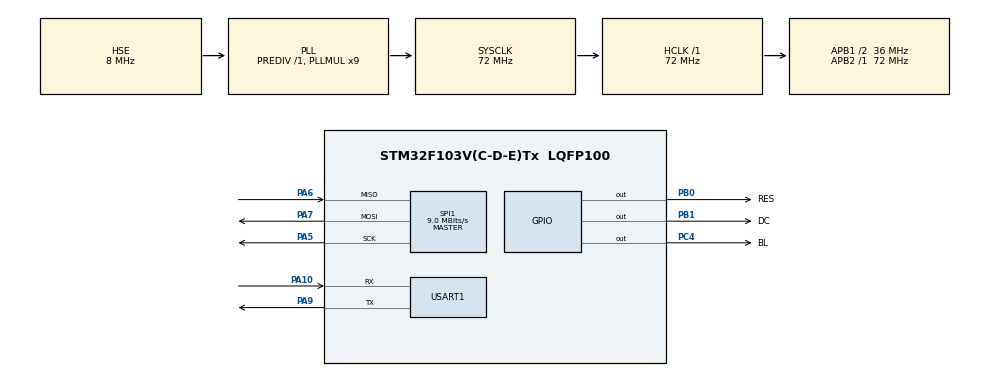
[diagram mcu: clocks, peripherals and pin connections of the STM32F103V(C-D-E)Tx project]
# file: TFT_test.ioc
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Mcu.Family=STM32F1
Mcu.Name=STM32F103V(C-D-E)Tx
Mcu.Package=LQFP100
NVIC.PriorityGroup=NVIC_PRIORITYGROUP_4
NVIC.USART1_IRQn=true\:0\:0\:false\:false\:true\:true\:true\:true
OSC_IN.Mode=HSE-External-Oscillator
OSC_IN.Signal=RCC_OSC_IN
OSC_OUT.Mode=HSE-External-Oscillator
OSC_OUT.Signal=RCC_OSC_OUT
PA10.Mode=Asynchronous
PA10.Signal=USART1_RX
PA13.Mode=JTAG_5_pins
PA13.Signal=SYS_JTMS-SWDIO
PA14.Mode=JTAG_5_pins
PA14.Signal=SYS_JTCK-SWCLK
PA15.Mode=JTAG_5_pins
PA15.Signal=SYS_JTDI
PA5.Mode=Full_Duplex_Master
PA5.Signal=SPI1_SCK
PA6.Mode=Full_Duplex_Master
PA6.Signal=SPI1_MISO
PA7.Mode=Full_Duplex_Master
PA7.Signal=SPI1_MOSI
PA9.Mode=Asynchronous
PA9.Signal=USART1_TX
PB0.GPIO_Label=RES
PB0.GPIO_Speed=GPIO_SPEED_FREQ_HIGH
PB0.PinState=GPIO_PIN_SET
PB0.Signal=GPIO_Output
PB1.GPIO_Label=DC
PB1.GPIO_Speed=GPIO_SPEED_FREQ_HIGH
PB1.PinState=GPIO_PIN_SET
PB1.Signal=GPIO_Output
PB3.Mode=JTAG_5_pins
PB3.Signal=SYS_JTDO-TRACESWO
PB4.Mode=JTAG_5_pins
PB4.Signal=SYS_NJTRST
PC4.GPIO_Label=BL
PC4.PinState=GPIO_PIN_SET
PC4.Signal=GPIO_Output
ProjectManager.HeapSize=0x200
ProjectManager.StackSize=0x400
ProjectManager.TargetToolchain=Makefile
RCC.AHBFreq_Value=72000000
RCC.APB1CLKDivider=RCC_HCLK_DIV2
RCC.APB1Freq_Value=36000000
RCC.APB1TimFreq_Value=72000000
RCC.APB2Freq_Value=72000000
RCC.APB2TimFreq_Value=72000000
RCC.HCLKFreq_Value=72000000
RCC.PLLMUL=RCC_PLL_MUL9
RCC.PLLSourceVirtual=RCC_PLLSOURCE_HSE
RCC.SYSCLKFreq_VALUE=72000000
RCC.SYSCLKSource=RCC_SYSCLKSOURCE_PLLCLK
RCC.USBFreq_Value=72000000
SPI1.BaudRatePrescaler=SPI_BAUDRATEPRESCALER_8
SPI1.CLKPolarity=SPI_POLARITY_HIGH
SPI1.CalculateBaudRate=9.0 MBits/s
SPI1.Direction=SPI_DIRECTION_2LINES
SPI1.Mode=SPI_MODE_MASTER
SPI1.VirtualType=VM_MASTER
USART1.VirtualMode=VM_ASYNC
board=custom

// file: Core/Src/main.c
/* USER CODE BEGIN Header */
/**
 ******************************************************************************
 * @file           : main.c
 * @brief          : Main program body
 ******************************************************************************
 * @attention
 *
 * Copyright (c) 2023 STMicroelectronics.
 * All rights reserved.
 *
 * This software is licensed under terms that can be found in the LICENSE file
 * in the root directory of this software component.
 * If no LICENSE file comes with this software, it is provided AS-IS.
 *
 ******************************************************************************
 */
/* USER CODE END Header */
#include "main.h"
#include "spi.h"
#include "usart.h"
#include "gpio.h"

/* USER CODE BEGIN Includes */
#include "spi_st7789.h"
/* USER CODE END Includes */

void SystemClock_Config(void);

int main(void)
{

  /* MCU Configuration--------------------------------------------------------*/

  /* Reset of all peripherals, Initializes the Flash interface and the Systick. */
  HAL_Init();

  /* Configure the system clock */
  SystemClock_Config();

  /* Initialize all configured peripherals */
  MX_GPIO_Init();
  MX_USART1_UART_Init();
  MX_SPI1_Init();
  /* USER CODE BEGIN 2 */
  st7789_init();
  int i = 0;
  //   ST7789_Init();
  /* USER CODE END 2 */

  /* Infinite loop */
  /* USER CODE BEGIN WHILE */
  while (1) {
    printf("init is ok%d\n", i++);
    HAL_Delay(1000);
    // ST7789_Test();

    /* USER CODE END WHILE */

  }
}

void SystemClock_Config(void)
{
  RCC_OscInitTypeDef RCC_OscInitStruct = {0};
  RCC_ClkInitTypeDef RCC_ClkInitStruct = {0};

  /** Initializes the RCC Oscillators according to the specified parameters
  * in the RCC_OscInitTypeDef structure.
  */
  RCC_OscInitStruct.OscillatorType = RCC_OSCILLATORTYPE_HSE;
  RCC_OscInitStruct.HSEState = RCC_HSE_ON;
  RCC_OscInitStruct.HSEPredivValue = RCC_HSE_PREDIV_DIV1;
  RCC_OscInitStruct.HSIState = RCC_HSI_ON;
  RCC_OscInitStruct.PLL.PLLState = RCC_PLL_ON;
  RCC_OscInitStruct.PLL.PLLSource = RCC_PLLSOURCE_HSE;
  RCC_OscInitStruct.PLL.PLLMUL = RCC_PLL_MUL9;
  if (HAL_RCC_OscConfig(&RCC_OscInitStruct) != HAL_OK)
  {
    Error_Handler();
  }

  /** Initializes the CPU, AHB and APB buses clocks
  */
  RCC_ClkInitStruct.ClockType = RCC_CLOCKTYPE_HCLK|RCC_CLOCKTYPE_SYSCLK
                              |RCC_CLOCKTYPE_PCLK1|RCC_CLOCKTYPE_PCLK2;
  RCC_ClkInitStruct.SYSCLKSource = RCC_SYSCLKSOURCE_PLLCLK;
  RCC_ClkInitStruct.AHBCLKDivider = RCC_SYSCLK_DIV1;
  RCC_ClkInitStruct.APB1CLKDivider = RCC_HCLK_DIV2;
  RCC_ClkInitStruct.APB2CLKDivider = RCC_HCLK_DIV1;

  if (HAL_RCC_ClockConfig(&RCC_ClkInitStruct, FLASH_LATENCY_2) != HAL_OK)
  {
    Error_Handler();
  }
}

void Error_Handler(void)
{
  __disable_irq();
  while (1) {
  }
}

#ifdef  USE_FULL_ASSERT
/**
  * @brief  Reports the name of the source file and the source line number
  *         where the assert_param error has occurred.
  * @param  file: pointer to the source file name
  * @param  line: assert_param error line source number
  * @retval None
  */
void assert_failed(uint8_t *file, uint32_t line)
{
  /* USER CODE BEGIN 6 */
  /* User can add his own implementation to report the file name and line
     number, ex: printf("Wrong parameters value: file %s on line %d\r\n", file,
     line) */
  /* USER CODE END 6 */
}
#endif /* USE_FULL_ASSERT */
